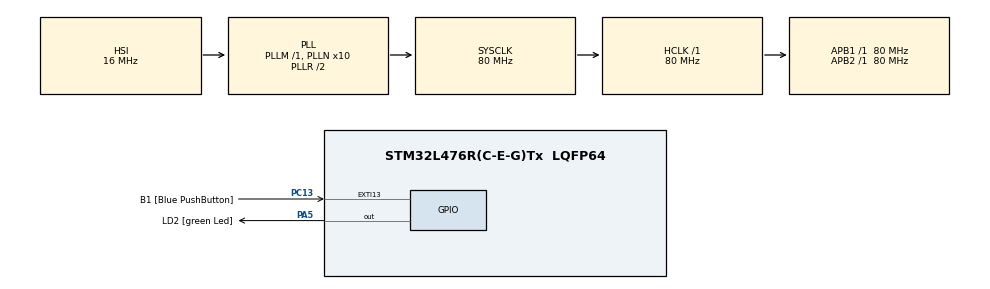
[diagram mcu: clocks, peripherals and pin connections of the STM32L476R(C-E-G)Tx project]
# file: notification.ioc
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Mcu.Family=STM32L4
Mcu.Name=STM32L476R(C-E-G)Tx
Mcu.Package=LQFP64
NVIC.PriorityGroup=NVIC_PRIORITYGROUP_4
NVIC.TIM6_DAC_IRQn=true\:15\:0\:false\:false\:true\:false\:true\:true
NVIC.TimeBase=TIM6_DAC_IRQn
NVIC.TimeBaseIP=TIM6
PA13\ (JTMS-SWDIO).GPIO_Label=TMS
PA13\ (JTMS-SWDIO).Signal=SYS_JTMS-SWDIO
PA14\ (JTCK-SWCLK).GPIO_Label=TCK
PA14\ (JTCK-SWCLK).Signal=SYS_JTCK-SWCLK
PA2.GPIO_Label=USART_TX
PA2.GPIO_Mode=GPIO_MODE_AF_PP
PA2.GPIO_PuPd=GPIO_NOPULL
PA2.GPIO_Speed=GPIO_SPEED_FREQ_VERY_HIGH
PA2.Signal=USART2_TX
PA3.GPIO_Label=USART_RX
PA3.GPIO_Mode=GPIO_MODE_AF_PP
PA3.GPIO_PuPd=GPIO_NOPULL
PA3.GPIO_Speed=GPIO_SPEED_FREQ_VERY_HIGH
PA3.Signal=USART2_RX
PA5.GPIO_Label=LD2 [green Led]
PA5.GPIO_ModeDefaultOutputPP=GPIO_MODE_OUTPUT_PP
PA5.GPIO_PuPd=GPIO_NOPULL
PA5.GPIO_Speed=GPIO_SPEED_FREQ_LOW
PA5.Signal=GPIO_Output
PB3\ (JTDO-TRACESWO).GPIO_Label=SWO
PB3\ (JTDO-TRACESWO).Signal=SYS_JTDO-SWO
PC13.GPIO_Label=B1 [Blue PushButton]
PC13.GPIO_ModeDefaultEXTI=GPIO_MODE_IT_FALLING
PC13.GPIO_PuPd=GPIO_NOPULL
PC13.Signal=GPXTI13
PC14-OSC32_IN\ (PC14).Signal=RCC_OSC32_IN
PC15-OSC32_OUT\ (PC15).Signal=RCC_OSC32_OUT
PH0-OSC_IN\ (PH0).Signal=RCC_OSC_IN
PH1-OSC_OUT\ (PH1).Signal=RCC_OSC_OUT
ProjectManager.HeapSize=0x200
ProjectManager.StackSize=0x400
ProjectManager.TargetToolchain=STM32CubeIDE
RCC.ADCFreq_Value=64000000
RCC.AHBFreq_Value=80000000
RCC.APB1Freq_Value=80000000
RCC.APB1TimFreq_Value=80000000
RCC.APB2Freq_Value=80000000
RCC.APB2TimFreq_Value=80000000
RCC.CortexFreq_Value=80000000
RCC.HCLKFreq_Value=80000000
RCC.HSE_VALUE=8000000
RCC.HSI_VALUE=16000000
RCC.LSE_VALUE=32768
RCC.MSI_VALUE=4000000
RCC.PLLN=10
RCC.PLLSourceVirtual=RCC_PLLSOURCE_HSI
RCC.PREFETCH_ENABLE=1
RCC.SYSCLKFreq_VALUE=80000000
RCC.SYSCLKSource=RCC_SYSCLKSOURCE_PLLCLK
RCC.USBFreq_Value=64000000
RCC.VCOOutputFreq_Value=160000000
VP_SYS_VS_tim6.Mode=TIM6
board=NUCLEO-L476RG

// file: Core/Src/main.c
/* USER CODE BEGIN Header */
/**
  ******************************************************************************
  * @file           : main.c
  * @brief          : Main program body
  ******************************************************************************
  * @attention
  *
  * Copyright (c) 2023 STMicroelectronics.
  * All rights reserved.
  *
  * This software is licensed under terms that can be found in the LICENSE file
  * in the root directory of this software component.
  * If no LICENSE file comes with this software, it is provided AS-IS.
  *
  ******************************************************************************
  */
/* USER CODE END Header */
#include "main.h"

/* USER CODE BEGIN Includes */
#include "FreeRTOS.h"
#include "task.h"
#include <stdio.h>
/* USER CODE END Includes */

/* USER CODE BEGIN PV */
#define DWT_CTRL  (*(volatile uint32_t*)0xE0001000)
/* USER CODE END PV */

void SystemClock_Config(void);
static void MX_GPIO_Init(void);
/* USER CODE BEGIN PFP */
void task1_handler(void *parameter);
void task2_handler(void *parameter);
void task3_handler(void *parameter);

/* USER CODE END PFP */

/* USER CODE BEGIN 0 */
TaskHandle_t task1_handle;
TaskHandle_t task2_handle;
TaskHandle_t task3_handle;
BaseType_t status;
/* USER CODE END 0 */

int main(void)
{

  /* MCU Configuration--------------------------------------------------------*/

  /* Reset of all peripherals, Initializes the Flash interface and the Systick. */
  HAL_Init();

  /* Configure the system clock */
  SystemClock_Config();

  /* Initialize all configured peripherals */
  MX_GPIO_Init();
  /* USER CODE BEGIN 2 */
  DWT_CTRL |= (1<<0);
  SEGGER_SYSVIEW_Conf();
  SEGGER_SYSVIEW_Start();
  status  = xTaskCreate(task1_handler, "Task1", 200, NULL, 2, &task1_handle);
  configASSERT(status == pdPASS);
  status = xTaskCreate(task2_handler, "Task2", 200, NULL, 2, &task2_handle);
  configASSERT(status == pdPASS);
  status = xTaskCreate(task3_handler, "Task3", 200, NULL, 2, &task3_handle);
  configASSERT(status == pdPASS);
  vTaskStartScheduler();
  /* USER CODE END 2 */

  /* Infinite loop */
  while (1)
  {

  }
}

void SystemClock_Config(void)
{
  RCC_OscInitTypeDef RCC_OscInitStruct = {0};
  RCC_ClkInitTypeDef RCC_ClkInitStruct = {0};

  /** Configure the main internal regulator output voltage
  */
  if (HAL_PWREx_ControlVoltageScaling(PWR_REGULATOR_VOLTAGE_SCALE1) != HAL_OK)
  {
    Error_Handler();
  }

  /** Initializes the RCC Oscillators according to the specified parameters
  * in the RCC_OscInitTypeDef structure.
  */
  RCC_OscInitStruct.OscillatorType = RCC_OSCILLATORTYPE_HSI;
  RCC_OscInitStruct.HSIState = RCC_HSI_ON;
  RCC_OscInitStruct.HSICalibrationValue = RCC_HSICALIBRATION_DEFAULT;
  RCC_OscInitStruct.PLL.PLLState = RCC_PLL_ON;
  RCC_OscInitStruct.PLL.PLLSource = RCC_PLLSOURCE_HSI;
  RCC_OscInitStruct.PLL.PLLM = 1;
  RCC_OscInitStruct.PLL.PLLN = 10;
  RCC_OscInitStruct.PLL.PLLP = RCC_PLLP_DIV7;
  RCC_OscInitStruct.PLL.PLLQ = RCC_PLLQ_DIV2;
  RCC_OscInitStruct.PLL.PLLR = RCC_PLLR_DIV2;
  if (HAL_RCC_OscConfig(&RCC_OscInitStruct) != HAL_OK)
  {
    Error_Handler();
  }

  /** Initializes the CPU, AHB and APB buses clocks
  */
  RCC_ClkInitStruct.ClockType = RCC_CLOCKTYPE_HCLK|RCC_CLOCKTYPE_SYSCLK
                              |RCC_CLOCKTYPE_PCLK1|RCC_CLOCKTYPE_PCLK2;
  RCC_ClkInitStruct.SYSCLKSource = RCC_SYSCLKSOURCE_PLLCLK;
  RCC_ClkInitStruct.AHBCLKDivider = RCC_SYSCLK_DIV1;
  RCC_ClkInitStruct.APB1CLKDivider = RCC_HCLK_DIV1;
  RCC_ClkInitStruct.APB2CLKDivider = RCC_HCLK_DIV1;

  if (HAL_RCC_ClockConfig(&RCC_ClkInitStruct, FLASH_LATENCY_4) != HAL_OK)
  {
    Error_Handler();
  }
}

static void MX_GPIO_Init(void)
{
  GPIO_InitTypeDef GPIO_InitStruct = {0};

  /* GPIO Ports Clock Enable */
  __HAL_RCC_GPIOC_CLK_ENABLE();
  __HAL_RCC_GPIOH_CLK_ENABLE();
  __HAL_RCC_GPIOA_CLK_ENABLE();
  __HAL_RCC_GPIOB_CLK_ENABLE();

  /*Configure GPIO pin Output Level */
  HAL_GPIO_WritePin(LD2_GPIO_Port, LD2_Pin, GPIO_PIN_RESET);

  /*Configure GPIO pin : B1_Pin */
  GPIO_InitStruct.Pin = B1_Pin;
  GPIO_InitStruct.Mode = GPIO_MODE_IT_FALLING;
  GPIO_InitStruct.Pull = GPIO_NOPULL;
  HAL_GPIO_Init(B1_GPIO_Port, &GPIO_InitStruct);

  /*Configure GPIO pins : USART_TX_Pin USART_RX_Pin */
  GPIO_InitStruct.Pin = USART_TX_Pin|USART_RX_Pin;
  GPIO_InitStruct.Mode = GPIO_MODE_AF_PP;
  GPIO_InitStruct.Pull = GPIO_NOPULL;
  GPIO_InitStruct.Speed = GPIO_SPEED_FREQ_VERY_HIGH;
  GPIO_InitStruct.Alternate = GPIO_AF7_USART2;
  HAL_GPIO_Init(GPIOA, &GPIO_InitStruct);

  /*Configure GPIO pin : LD2_Pin */
  GPIO_InitStruct.Pin = LD2_Pin;
  GPIO_InitStruct.Mode = GPIO_MODE_OUTPUT_PP;
  GPIO_InitStruct.Pull = GPIO_NOPULL;
  GPIO_InitStruct.Speed = GPIO_SPEED_FREQ_LOW;
  HAL_GPIO_Init(LD2_GPIO_Port, &GPIO_InitStruct);

}

/* USER CODE BEGIN 4 */
//----------------------------------------------------------------------------------------------------------
//xxxxxxxxxxxxxxxxxxxxxxxxxxxx Exercise 1 - Single Notification xxxxxxxxxxxxxxxxxxxxxxxxxxxxxxxxxxxxxxxxxxxx
//----------------------------------------------------------------------------------------------------------
void task1_handler(void *parameter)
{
	while(1){
		xTaskNotifyGive(task2_handle);
		xTaskNotifyGive(task2_handle);
		xTaskNotifyGive(task2_handle);
		vTaskDelay(pdMS_TO_TICKS(1000));
//		xTaskNotifyGive(task3_handle);
//		vTaskDelay(pdMS_TO_TICKS(1000));
	}
}

void task2_handler(void *parameter)
{
	int not_val;
	while(1){
		not_val = ulTaskNotifyTake(pdTRUE, (TickType_t)portMAX_DELAY);   // pdTrue reset the notification value to 0, whereas pdFalse decrements the value in case of multiple values
		if(not_val > 0 ){
			printf("Notification Recieved in Task 2 = %d \n", not_val);
		}
	}
}

void task3_handler(void *parameter)
{
	int not_val;
	while(1){
		not_val = ulTaskNotifyTake(pdTRUE, (TickType_t)portMAX_DELAY);   // pdTrue reset the notification value to 0, whereas pdFalse decrements the value in cas of multiple values
		if(not_val > 0 ){
			printf("Notification Recieved in task 3 %d \n", not_val);
		}
	}
}

//-------------------------------------------------------------------------------------
//xxxxxxxxxxxxxxxxxxxxxxxxxxxx Exercise 2 - Multiple Notification xxxxxxxxxxxxxxxxxxxxxxxxxxxxxxxxxxxxxxxxxxxx
//--------------------------------------------------------------------------------------
//void task1_handler(void *parameter)
//{
//	while(1){
//		xTaskNotifyGive(task2_handle);
//		xTaskNotifyGive(task2_handle);
//		vTaskDelay(pdMS_TO_TICKS(1000));
//		xTaskNotifyGive(task3_handle);
//		xTaskNotifyGive(task3_handle);
//		vTaskDelay(pdMS_TO_TICKS(1000));
//	}
//}
//
//void task2_handler(void *parameter)
//{
//	int not_val;
//	while(1){
//		not_val = ulTaskNotifyTake(pdFALSE, (TickType_t)portMAX_DELAY);   // pdTrue reset the notification value to 0, whereas pdFalse decrements the value in cas of multiple values
//		if(not_val > 0 ){
//			printf("Notification Recieved in Task 2 %d \n", not_val);
//		}
//	}
//}
//
//void task3_handler(void *parameter)
//{
//	int not_val;
//	while(1){
//		not_val = ulTaskNotifyTake(pdFALSE, (TickType_t)portMAX_DELAY);   // pdTrue reset the notification value to 0, whereas pdFalse decrements the value in cas of multiple values
//		if(not_val > 0 ){
//			printf("Notification Recieved in task 3 %d \n", not_val);
//		}
//	}
//}
//

//----------------------------------------------------------------------------------------------------------------
//xxxxxxxxxxxxxxxxxxxxxxxxxxxx Exercise 3 - Notification with actions xxxxxxxxxxxxxxxxxxxxxxxxxxxxxxxxxxxxxxxxxxxx
//----------------------------------------------------------------------------------------------------------------
//void task1_handler(void *parameter)
//{
//	while(1){
//		xTaskNotify(task2_handle,(1<<0)|(1<<1)|(1<<2), eSetBits);
//
////	    eNoAction = 0,                /* Notify the task without updating its notify value. */
////	    eSetBits,                     /* Set bits in the task's notification value. */
////	    eIncrement,                   /* Increment the task's notification value. */
////	    eSetValueWithOverwrite,       /* Set the task's notification value to a specific value even if the previous value has not yet been read by the task. */
////	    eSetValueWithoutOverwrite     /* Set the task's notification value if the previous value has been read by the task. */
//
//		vTaskDelay(pdMS_TO_TICKS(1000));
////		xTaskNotify(task3_handle,(1<<3)|(1<<4)|(1<<5), eSetBits);
////		vTaskDelay(pdMS_TO_TICKS(1000));
//	}
//}
//
//void task2_handler(void *parameter)
//{
//	while(1){
//		uint32_t not_val;
//		if(xTaskNotifyWait(0, 0, &not_val, portMAX_DELAY)== pdTRUE){
//			printf("Notification Recieved tsk2 %d \n", not_val);
//		}
//	}
//}
//
//void task3_handler(void *parameter)
//{
//	while(1){
//		uint32_t not_val;
//		if(xTaskNotifyWait(0, 0, &not_val, portMAX_DELAY)== pdTRUE){
//			printf("Notification Recieved tsk3 %d \n", not_val);
//		}
//	}
//}

//----------------------------------------------------------------------------------------------------------------
//xxxxxxxxxxxxxxxxxxxxxxxxxxxx Exercise 4 - Notification with actions xxxxxxxxxxxxxxxxxxxxxxxxxxxxxxxxxxxxxxxxxxxx
//----------------------------------------------------------------------------------------------------------------
//void task1_handler(void *parameter)
//{
//	while(1){
//		xTaskNotify(task2_handle,(1<<0), eSetBits);
//		vTaskDelay(pdMS_TO_TICKS(1000));
//		xTaskNotify(task2_handle,(1<<1), eSetBits);
//		vTaskDelay(pdMS_TO_TICKS(1000));
//		xTaskNotify(task2_handle,(1<<2), eSetBits);
//		vTaskDelay(pdMS_TO_TICKS(1000));
////	    eNoAction = 0,                /* Notify the task without updating its notify value. */
////	    eSetBits,                     /* Set bits in the task's notification value. */
////	    eIncrement,                   /* Increment the task's notification value. */
////	    eSetValueWithOverwrite,       /* Set the task's notification value to a specific value even if the previous value has not yet been read by the task. */
////	    eSetValueWithoutOverwrite     /* Set the task's notification value if the previous value has been read by the task. */
//
////		vTaskDelay(pdMS_TO_TICKS(1000));
////		xTaskNotify(task3_handle,(1<<3)|(1<<4)|(1<<5), eSetBits);
////		vTaskDelay(pdMS_TO_TICKS(1000));
//	}
//}
//
//void task2_handler(void *parameter)
//{
//	while(1){
//		uint32_t not_val;
//		if(xTaskNotifyWait(0, 0, &not_val, portMAX_DELAY)== pdTRUE){
//			printf("Notification Recieved tsk2 %d \n", not_val);
//		}
//	}
//}
//
//void task3_handler(void *parameter)
//{
//	while(1){
//		uint32_t not_val;
//		if(xTaskNotifyWait(0, 0, &not_val, portMAX_DELAY)== pdTRUE){
//			printf("Notification Recieved tsk2 %d \n", not_val);
//		}
//	}
//}

//----------------------------------------------------------------------------------------------------------------
//xxxxxxxxxxxxxxxxxxxxxxxxxxxx Exercise 5 - Notification with actions xxxxxxxxxxxxxxxxxxxxxxxxxxxxxxxxxxxxxxxxxxxx
//----------------------------------------------------------------------------------------------------------------
//void task1_handler(void *parameter)
//{
//	while(1){
//		xTaskNotify(task2_handle,(1<<0), eSetValueWithOverwrite);
//		vTaskDelay(pdMS_TO_TICKS(1000));
//		xTaskNotify(task2_handle,(1<<1), eSetValueWithOverwrite);
//		vTaskDelay(pdMS_TO_TICKS(1000));
//		xTaskNotify(task2_handle,(1<<2), eSetValueWithOverwrite);
//		vTaskDelay(pdMS_TO_TICKS(1000));
////	    eNoAction = 0,                /* Notify the task without updating its notify value. */
////	    eSetBits,                     /* Set bits in the task's notification value. */
////	    eIncrement,                   /* Increment the task's notification value. */
////	    eSetValueWithOverwrite,       /* Set the task's notification value to a specific value even if the previous value has not yet been read by the task. */
////	    eSetValueWithoutOverwrite     /* Set the task's notification value if the previous value has been read by the task. */
//
////		vTaskDelay(pdMS_TO_TICKS(1000));
////		xTaskNotify(task3_handle,(1<<3)|(1<<4)|(1<<5), eSetBits);
////		vTaskDelay(pdMS_TO_TICKS(1000));
//	}
//}
//
//void task2_handler(void *parameter)
//{
//	while(1){
//		uint32_t not_val;
//		if(xTaskNotifyWait(0, 0, &not_val, portMAX_DELAY)== pdTRUE){
//			printf("Notification Recieved tsk2 %d \n", not_val);
//		}
//	}
//}
//
//void task3_handler(void *parameter)
//{
//	while(1){
//		uint32_t not_val;
//		if(xTaskNotifyWait(0, 0, &not_val, portMAX_DELAY)== pdTRUE){
//			printf("Notification Recieved tsk2 %d \n", not_val);
//		}
//	}
//}

//----------------------------------------------------------------------------------------------------------------
//xxxxxxxxxxxxxxxxxxxxxxxxxxxx Exercise 6 - Notification with actions xxxxxxxxxxxxxxxxxxxxxxxxxxxxxxxxxxxxxxxxxxxx
//----------------------------------------------------------------------------------------------------------------
//void task1_handler(void *parameter)
//{
//	while(1){
//		xTaskNotify(task2_handle,(1<<0), eSetBits);
//		vTaskDelay(pdMS_TO_TICKS(1000));
//		xTaskNotify(task2_handle,(1<<1), eSetBits);
//		vTaskDelay(pdMS_TO_TICKS(1000));
//		xTaskNotify(task2_handle,(1<<2), eSetBits);
//		vTaskDelay(pdMS_TO_TICKS(1000));
////	    eNoAction = 0,                /* Notify the task without updating its notify value. */
////	    eSetBits,                     /* Set bits in the task's notification value. */
////	    eIncrement,                   /* Increment the task's notification value. */
////	    eSetValueWithOverwrite,       /* Set the task's notification value to a specific value even if the previous value has not yet been read by the task. */
////	    eSetValueWithoutOverwrite     /* Set the task's notification value if the previous value has been read by the task. */
//
////		vTaskDelay(pdMS_TO_TICKS(1000));
////		xTaskNotify(task3_handle,(1<<3)|(1<<4)|(1<<5), eSetBits);
////		vTaskDelay(pdMS_TO_TICKS(1000));
//	}
//}
//
//void task2_handler(void *parameter)
//{
//	while(1){
//		uint32_t not_val;
//		if(xTaskNotifyWait((1<<0)|(1<<1)|(1<<2), 0, &not_val, portMAX_DELAY)== pdTRUE){   // 1st parameter is used to clear the bits set on entry
//			printf("Notification Recieved tsk2 %d \n", not_val);
//		}
//	}
//}
//
//void task3_handler(void *parameter)
//{
//	while(1){
//		uint32_t not_val;
//		if(xTaskNotifyWait(0, 0, &not_val, portMAX_DELAY)== pdTRUE){
//			printf("Notification Recieved tsk2 %d \n", not_val);
//		}
//	}
//}

////----------------------------------------------------------------------------------------------------------------
////xxxxxxxxxxxxxxxxxxxxxxxxxxxx Exercise 7 - Notification with actions xxxxxxxxxxxxxxxxxxxxxxxxxxxxxxxxxxxxxxxxxxxx
////----------------------------------------------------------------------------------------------------------------
//void task1_handler(void *parameter)
//{
//	while(1){
//		xTaskNotify(task2_handle,(1<<0), eSetBits);
//		vTaskDelay(pdMS_TO_TICKS(1000));
//		xTaskNotify(task2_handle,(1<<1), eSetBits);
//		vTaskDelay(pdMS_TO_TICKS(1000));
//		xTaskNotify(task2_handle,(1<<2), eSetBits);
//		vTaskDelay(pdMS_TO_TICKS(1000));
////	    eNoAction = 0,                /* Notify the task without updating its notify value. */
////	    eSetBits,                     /* Set bits in the task's notification value. */
////	    eIncrement,                   /* Increment the task's notification value. */
////	    eSetValueWithOverwrite,       /* Set the task's notification value to a specific value even if the previous value has not yet been read by the task. */
////	    eSetValueWithoutOverwrite     /* Set the task's notification value if the previous value has been read by the task. */
//
////		vTaskDelay(pdMS_TO_TICKS(1000));
////		xTaskNotify(task3_handle,(1<<3)|(1<<4)|(1<<5), eSetBits);
////		vTaskDelay(pdMS_TO_TICKS(1000));
//	}
//}
//
//void task2_handler(void *parameter)
//{
//	while(1){
//		uint32_t not_val;
//		if(xTaskNotifyWait(0,(1<<0)|(1<<1)|(1<<2), &not_val, portMAX_DELAY)== pdTRUE){   // 2nd parameter is used to clear the bits on exit
//			printf("Notification Recieved tsk2 %d \n", not_val);
//		}
//	}
//}
//
//void task3_handler(void *parameter)
//{
//	while(1){
//		uint32_t not_val;
//		if(xTaskNotifyWait(0, 0, &not_val, portMAX_DELAY)== pdTRUE){
//			printf("Notification Recieved tsk2 %d \n", not_val);
//		}
//	}
//}

//----------------------------------------------------------------------------------------------------------------
//xxxxxxxxxxxxxxxxxxxxxxxxxxxx Exercise 8 - Notification with actions xxxxxxxxxxxxxxxxxxxxxxxxxxxxxxxxxxxxxxxxxxxx
//----------------------------------------------------------------------------------------------------------------
//void task1_handler(void *parameter)
//{
//	while(1){
//		xTaskNotify(task2_handle,(1<<0), eSetBits);
//		xTaskNotify(task3_handle,(1<<0), eSetBits);
//		vTaskDelay(pdMS_TO_TICKS(3000));
//		xTaskNotify(task2_handle,(1<<1), eSetBits);
//		xTaskNotify(task3_handle,(1<<1), eSetBits);
//		vTaskDelay(pdMS_TO_TICKS(3000));
//		xTaskNotify(task2_handle,(1<<2), eSetBits);
//		xTaskNotify(task3_handle,(1<<2), eSetBits);
//		vTaskDelay(pdMS_TO_TICKS(3000));
////	    eNoAction = 0,                /* Notify the task without updating its notify value. */
////	    eSetBits,                     /* Set bits in the task's notification value. */
////	    eIncrement,                   /* Increment the task's notification value. */
////	    eSetValueWithOverwrite,       /* Set the task's notification value to a specific value even if the previous value has not yet been read by the task. */
////	    eSetValueWithoutOverwrite     /* Set the task's notification value if the previous value has been read by the task. */
//
////		vTaskDelay(pdMS_TO_TICKS(1000));
////		xTaskNotify(task3_handle,(1<<3)|(1<<4)|(1<<5), eSetBits);
////		vTaskDelay(pdMS_TO_TICKS(1000));
//	}
//}
//
//void task2_handler(void *parameter)
//{
//	uint32_t not_val;
//	while(1){
//		if(xTaskNotifyWait(0xFFFFFFFF,0, &not_val, portMAX_DELAY)== pdTRUE){
//			if(not_val & (1<<0)){
//				printf("Red LED ON\n");
//			}
//			else if(not_val & (1<<1)){
//				printf("Yellow LED ON\n");
//			}
//			else if(not_val & (1<<2)){
//				printf("Green LED ON\n");
//			}
//		}
//	}
//}
//
//void task3_handler(void *parameter)
//{
//	uint32_t not_val;
//	while(1){
//		if(xTaskNotifyWait(0xFFFFFFFF,0, &not_val, portMAX_DELAY)== pdTRUE){   // 2nd parameter is used to clear the bits on exit
//			if(not_val & (1<<0)){
//				printf("Green LED ON\n");
//			}
//			else if(not_val & (1<<1)){
//				printf("Yellow LED ON\n");
//			}
//			else if(not_val & (1<<2)){
//				printf("RED LED ON\n");
//			}
//		}
//	}
//}
/* USER CODE END 4 */

void HAL_TIM_PeriodElapsedCallback(TIM_HandleTypeDef *htim)
{
  if (htim->Instance == TIM6) {
    HAL_IncTick();
  }
}

void Error_Handler(void)
{
  __disable_irq();
  while (1)
  {
  }
}
